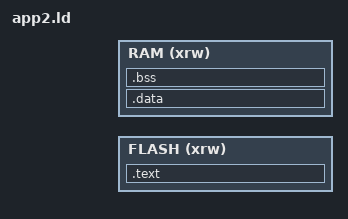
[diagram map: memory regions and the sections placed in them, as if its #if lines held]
#include "mem_map.h"
ENTRY(app_entry)

IMAGE_HEAD = APP_IMAGE_HEAD;
#ifdef APP2_IMAGE_FLASH_LOAD_ADDR

APP_FLASH_ADDR = APP2_IMAGE_FLASH_LOAD_ADDR;
#else
APP_FLASH_ADDR = 0x0;
#endif

#ifdef APP2_IMAGE_FLASH_LOAD_SIZE
APP_FLASH_SIZE = APP2_IMAGE_FLASH_LOAD_SIZE;
APP_RAM_ADDR = APP_RAM_ADDR_START - APP_RAM_DATA_SIZE - APP2_RAM_DATA_SIZE; /*up_buf_start - APP_RAM_SIZE*/
APP_RAM_SIZE = APP2_RAM_DATA_SIZE;
#else
APP_FLASH_SIZE = 0x0;
APP_RAM_ADDR = 0x0;
APP_RAM_SIZE = 0x0;
#endif

MEMORY
{
    FLASH (xrw)   : ORIGIN = APP_FLASH_ADDR + IMAGE_HEAD, 	LENGTH = APP_FLASH_SIZE - IMAGE_HEAD	
    RAM (xrw)     : ORIGIN = APP_RAM_ADDR, 					LENGTH = APP_RAM_SIZE
}

FLASH_TOTAL = LENGTH(FLASH);
FLASH_USED = SIZEOF(.text)+SIZEOF(.data);
RAM_TOTAL = LENGTH(RAM);
RAM_USED = SIZEOF(.data)+SIZEOF(.bss);

__stack = ORIGIN(RAM) + LENGTH(RAM);

SECTIONS
{
    .text : ALIGN(4)
    {
        KEEP(*(.text.app_entry))

        *(.text.* .text)								/* all remaining code in ram */

        *(.ramtext*)									/* attribute used */

        *(.rodata .rodata.* .constdata .constdata.*)	/* read only or const data */

        *(vtable)										/* C++ virtual tables */

        KEEP(*(.eh_frame*))

        /*
        * Stub sections generated by the linker, to glue together 
        * ARM and Thumb code. .glue_7 is used for ARM code calling 
        * Thumb code, and .glue_7t is used for Thumb code calling 
        * ARM code. Apparently always generated by the linker, for some
        * architectures, so better leave them here.
        */
        *(.glue_7)
        *(.glue_7t)
    } >FLASH

    __data_flash_addr__ = .;


    .data : ALIGN(4)
    {
        FILL(0xFF)
            /* This is used by the startup code to initialise the .data section */
            __data_start__ = . ;
        *(.data_begin .data_begin.*)

            *(.data .data.*)

            *(.data_end .data_end.*)
            . = ALIGN(4);

        /* This is used by the startup code to initialise the .data section */
        __data_end__ = . ;

    } >RAM

    /* The primary uninitialised data section. */
    .bss (NOLOAD) : ALIGN(4)
    {
        __bss_start__ = .;     	/* standard newlib definition */
        *(.bss_begin .bss_begin.*)

            *(.bss .bss.*)
            *(COMMON)

            *(.bss_end .bss_end.*)
            . = ALIGN(4);
        __bss_end__ = .;        /* standard newlib definition */
    } >RAM
	
    /* Check if sram + flash exceeds Flash Total limit */
    ASSERT(FLASH_USED < FLASH_TOTAL, "flash used size exceeds flash total size")
        /* check ram limit */
    ASSERT(RAM_USED < RAM_TOTAL, "ram used size exceeds ram total size")
}
